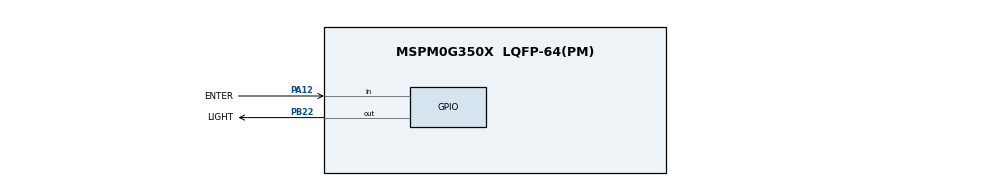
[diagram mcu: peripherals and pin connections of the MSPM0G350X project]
/**
 * @cliArgs --device "MSPM0G350X" --part "Default" --package "LQFP-64(PM)" --product "mspm0_sdk@2.10.00.04"
 * @versions {"tool":"1.27.1+4634"}
 */

/**
 * Import the modules used in this configuration.
 */
const GPIO   = scripting.addModule("/ti/driverlib/GPIO", {}, false);
const GPIO1  = GPIO.addInstance();
const GPIO2  = GPIO.addInstance();
const GPIO3  = GPIO.addInstance();
const SYSCTL = scripting.addModule("/ti/driverlib/SYSCTL");
const TIMER  = scripting.addModule("/ti/driverlib/TIMER", {}, false);
const TIMER1 = TIMER.addInstance();

/**
 * Write custom configuration values to the imported modules.
 */
const divider2       = system.clockTree["HFCLK4MFPCLKDIV"];
divider2.divideValue = 10;

const divider9       = system.clockTree["UDIV"];
divider9.divideValue = 2;

const gate8  = system.clockTree["MFPCLKGATE"];
gate8.enable = true;

const mux4       = system.clockTree["EXHFMUX"];
mux4.inputSelect = "EXHFMUX_XTAL";

const mux8       = system.clockTree["HSCLKMUX"];
mux8.inputSelect = "HSCLKMUX_SYSPLL2X";

const mux10       = system.clockTree["MFPCLKMUX"];
mux10.inputSelect = "MFPCLKMUX_HFCLK";

const mux12       = system.clockTree["SYSPLLMUX"];
mux12.inputSelect = "zSYSPLLMUX_HFCLK";

const pinFunction4     = system.clockTree["HFXT"];
pinFunction4.enable    = true;
pinFunction4.inputFreq = 40;

GPIO1.$name                                 = "OLED_SPI";
GPIO1.associatedPins.create(6);
GPIO1.associatedPins[0].$name               = "SCL";
GPIO1.associatedPins[0].initialValue        = "SET";
GPIO1.associatedPins[0].internalResistor    = "PULL_UP";
GPIO1.associatedPins[0].assignedPort        = "PORTA";
GPIO1.associatedPins[0].assignedPin         = "0";
GPIO1.associatedPins[0].assignedPortSegment = "Lower";
GPIO1.associatedPins[1].$name               = "SDA";
GPIO1.associatedPins[1].initialValue        = "SET";
GPIO1.associatedPins[1].internalResistor    = "PULL_UP";
GPIO1.associatedPins[1].assignedPort        = "PORTA";
GPIO1.associatedPins[1].assignedPin         = "1";
GPIO1.associatedPins[2].$name               = "RES";
GPIO1.associatedPins[2].assignedPort        = "PORTA";
GPIO1.associatedPins[2].assignedPin         = "8";
GPIO1.associatedPins[2].internalResistor    = "PULL_UP";
GPIO1.associatedPins[3].$name               = "DC";
GPIO1.associatedPins[3].assignedPort        = "PORTA";
GPIO1.associatedPins[3].internalResistor    = "PULL_UP";
GPIO1.associatedPins[3].assignedPin         = "9";
GPIO1.associatedPins[4].$name               = "CS";
GPIO1.associatedPins[4].assignedPort        = "PORTB";
GPIO1.associatedPins[4].assignedPin         = "15";
GPIO1.associatedPins[4].internalResistor    = "PULL_UP";
GPIO1.associatedPins[5].$name               = "BLK";
GPIO1.associatedPins[5].assignedPort        = "PORTB";
GPIO1.associatedPins[5].assignedPin         = "16";
GPIO1.associatedPins[5].internalResistor    = "PULL_UP";

const Board = scripting.addModule("/ti/driverlib/Board", {}, false);

GPIO2.$name                         = "LED";
GPIO2.port                          = "PORTB";
GPIO2.portSegment                   = "Upper";
GPIO2.associatedPins[0].$name       = "LIGHT";
GPIO2.associatedPins[0].assignedPin = "22";
GPIO2.associatedPins[0].pin.$assign = "PB22";

GPIO3.$name                              = "KEY";
GPIO3.associatedPins.create(3);
GPIO3.associatedPins[0].$name            = "UP";
GPIO3.associatedPins[0].direction        = "INPUT";
GPIO3.associatedPins[0].internalResistor = "PULL_DOWN";
GPIO3.associatedPins[0].assignedPort     = "PORTB";
GPIO3.associatedPins[0].assignedPin      = "27";
GPIO3.associatedPins[1].$name            = "DOWN";
GPIO3.associatedPins[1].direction        = "INPUT";
GPIO3.associatedPins[1].internalResistor = "PULL_DOWN";
GPIO3.associatedPins[1].assignedPort     = "PORTB";
GPIO3.associatedPins[1].assignedPin      = "23";
GPIO3.associatedPins[2].$name            = "ENTER";
GPIO3.associatedPins[2].direction        = "INPUT";
GPIO3.associatedPins[2].internalResistor = "PULL_DOWN";
GPIO3.associatedPins[2].pin.$assign      = "PA12";

SYSCTL.forceDefaultClkConfig = true;

TIMER1.$name = "TIMER_0";

/**
 * Pinmux solution for unlocked pins/peripherals. This ensures that minor changes to the automatic solver in a future
 * version of the tool will not impact the pinmux you originally saw.  These lines can be completely deleted in order to
 * re-solve from scratch.
 */
pinFunction4.peripheral.$suggestSolution           = "SYSCTL";
pinFunction4.peripheral.hfxInPin.$suggestSolution  = "PA5";
pinFunction4.peripheral.hfxOutPin.$suggestSolution = "PA6";
GPIO1.associatedPins[0].pin.$suggestSolution       = "PA0";
GPIO1.associatedPins[1].pin.$suggestSolution       = "PA1";
GPIO1.associatedPins[2].pin.$suggestSolution       = "PA8";
GPIO1.associatedPins[3].pin.$suggestSolution       = "PA9";
GPIO1.associatedPins[4].pin.$suggestSolution       = "PB15";
GPIO1.associatedPins[5].pin.$suggestSolution       = "PB16";
Board.peripheral.$suggestSolution                  = "DEBUGSS";
Board.peripheral.swclkPin.$suggestSolution         = "PA20";
Board.peripheral.swdioPin.$suggestSolution         = "PA19";
GPIO3.associatedPins[0].pin.$suggestSolution       = "PB27";
GPIO3.associatedPins[1].pin.$suggestSolution       = "PB23";
SYSCTL.peripheral.$suggestSolution                 = "SYSCTL";
TIMER1.peripheral.$suggestSolution                 = "TIMA0";
